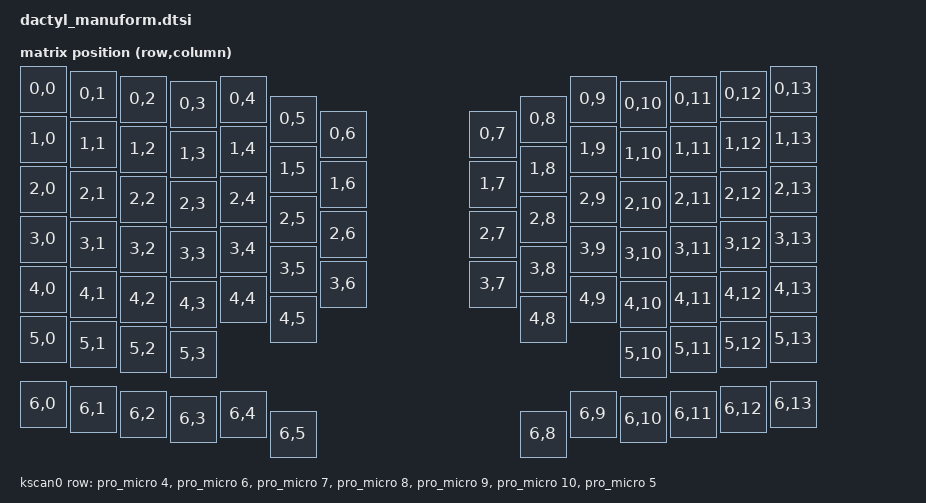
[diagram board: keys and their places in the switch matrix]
#include <dt-bindings/zmk/matrix_transform.h>
#include <physical_layouts.dtsi>

/ {
	chosen {
		zmk,kscan = &kscan0;
		zmk,physical-layout = &dactyl_manuform_layout;
	};

	dactyl_manuform_layout: dactyl_manuform_layout {
		compatible = "zmk,physical-layout";
		display-name = "7x7";
		transform = <&default_transform>;

		keys = <&key_physical_attrs 100 100 0 0 0 0 0>
			, <&key_physical_attrs 100 100 100 10 0 0 0>
			, <&key_physical_attrs 100 100 200 20 0 0 0>
			, <&key_physical_attrs 100 100 300 30 0 0 0>
			, <&key_physical_attrs 100 100 400 20 0 0 0>
			, <&key_physical_attrs 100 100 500 60 0 0 0>
			, <&key_physical_attrs 100 100 600 90 0 0 0>
			, <&key_physical_attrs 100 100 900 90 0 0 0>
			, <&key_physical_attrs 100 100 1000 60 0 0 0>
			, <&key_physical_attrs 100 100 1100 20 0 0 0>
			, <&key_physical_attrs 100 100 1200 30 0 0 0>
			, <&key_physical_attrs 100 100 1300 20 0 0 0>
			, <&key_physical_attrs 100 100 1400 10 0 0 0>
			, <&key_physical_attrs 100 100 1500 0 0 0 0>
			, <&key_physical_attrs 100 100 0 100 0 0 0>
			, <&key_physical_attrs 100 100 100 110 0 0 0>
			, <&key_physical_attrs 100 100 200 120 0 0 0>
			, <&key_physical_attrs 100 100 300 130 0 0 0>
			, <&key_physical_attrs 100 100 400 120 0 0 0>
			, <&key_physical_attrs 100 100 500 160 0 0 0>
			, <&key_physical_attrs 100 100 600 190 0 0 0>
			, <&key_physical_attrs 100 100 900 190 0 0 0>
			, <&key_physical_attrs 100 100 1000 160 0 0 0>
			, <&key_physical_attrs 100 100 1100 120 0 0 0>
			, <&key_physical_attrs 100 100 1200 130 0 0 0>
			, <&key_physical_attrs 100 100 1300 120 0 0 0>
			, <&key_physical_attrs 100 100 1400 110 0 0 0>
			, <&key_physical_attrs 100 100 1500 100 0 0 0>
			, <&key_physical_attrs 100 100 0 200 0 0 0>
			, <&key_physical_attrs 100 100 100 210 0 0 0>
			, <&key_physical_attrs 100 100 200 220 0 0 0>
			, <&key_physical_attrs 100 100 300 230 0 0 0>
			, <&key_physical_attrs 100 100 400 220 0 0 0>
			, <&key_physical_attrs 100 100 500 260 0 0 0>
			, <&key_physical_attrs 100 100 600 290 0 0 0>
			, <&key_physical_attrs 100 100 900 290 0 0 0>
			, <&key_physical_attrs 100 100 1000 260 0 0 0>
			, <&key_physical_attrs 100 100 1100 220 0 0 0>
			, <&key_physical_attrs 100 100 1200 230 0 0 0>
			, <&key_physical_attrs 100 100 1300 220 0 0 0>
			, <&key_physical_attrs 100 100 1400 210 0 0 0>
			, <&key_physical_attrs 100 100 1500 200 0 0 0>
			, <&key_physical_attrs 100 100 0 300 0 0 0>
			, <&key_physical_attrs 100 100 100 310 0 0 0>
			, <&key_physical_attrs 100 100 200 320 0 0 0>
			, <&key_physical_attrs 100 100 300 330 0 0 0>
			, <&key_physical_attrs 100 100 400 320 0 0 0>
			, <&key_physical_attrs 100 100 500 360 0 0 0>
			, <&key_physical_attrs 100 100 600 390 0 0 0>
			, <&key_physical_attrs 100 100 900 390 0 0 0>
			, <&key_physical_attrs 100 100 1000 360 0 0 0>
			, <&key_physical_attrs 100 100 1100 320 0 0 0>
			, <&key_physical_attrs 100 100 1200 330 0 0 0>
			, <&key_physical_attrs 100 100 1300 320 0 0 0>
			, <&key_physical_attrs 100 100 1400 310 0 0 0>
			, <&key_physical_attrs 100 100 1500 300 0 0 0>
			, <&key_physical_attrs 100 100 0 400 0 0 0>
			, <&key_physical_attrs 100 100 100 410 0 0 0>
			, <&key_physical_attrs 100 100 200 420 0 0 0>
			, <&key_physical_attrs 100 100 300 430 0 0 0>
			, <&key_physical_attrs 100 100 400 420 0 0 0>
			, <&key_physical_attrs 100 100 500 460 0 0 0>
			, <&key_physical_attrs 100 100 1000 460 0 0 0>
			, <&key_physical_attrs 100 100 1100 420 0 0 0>
			, <&key_physical_attrs 100 100 1200 430 0 0 0>
			, <&key_physical_attrs 100 100 1300 420 0 0 0>
			, <&key_physical_attrs 100 100 1400 410 0 0 0>
			, <&key_physical_attrs 100 100 1500 400 0 0 0>
			, <&key_physical_attrs 100 100 0 500 0 0 0>
			, <&key_physical_attrs 100 100 100 510 0 0 0>
			, <&key_physical_attrs 100 100 200 520 0 0 0>
			, <&key_physical_attrs 100 100 300 530 0 0 0>
			, <&key_physical_attrs 100 100 1200 530 0 0 0>
			, <&key_physical_attrs 100 100 1300 520 0 0 0>
			, <&key_physical_attrs 100 100 1400 510 0 0 0>
			, <&key_physical_attrs 100 100 1500 500 0 0 0>
			, <&key_physical_attrs 100 100 0 630 0 0 0>
			, <&key_physical_attrs 100 100 100 640 0 0 0>
			, <&key_physical_attrs 100 100 200 650 0 0 0>
			, <&key_physical_attrs 100 100 300 660 0 0 0>
			, <&key_physical_attrs 100 100 400 650 0 0 0>
			, <&key_physical_attrs 100 100 500 690 0 0 0>
			, <&key_physical_attrs 100 100 1000 690 0 0 0>
			, <&key_physical_attrs 100 100 1100 650 0 0 0>
			, <&key_physical_attrs 100 100 1200 660 0 0 0>
			, <&key_physical_attrs 100 100 1300 650 0 0 0>
			, <&key_physical_attrs 100 100 1400 640 0 0 0>
			, <&key_physical_attrs 100 100 1500 630 0 0 0>
		;
	};

	default_transform: keymap_transform_0 {
		compatible = "zmk,matrix-transform";
		columns = <14>;
		rows = <7>;
		map = <
RC(0,0) RC(0,1) RC(0,2) RC(0,3) RC(0,4) RC(0,5) RC(0,6)                                   RC(0,7) RC(0,8) RC(0,9) RC(0,10) RC(0,11) RC(0,12) RC(0,13)
RC(1,0) RC(1,1) RC(1,2) RC(1,3) RC(1,4) RC(1,5) RC(1,6)                                   RC(1,7) RC(1,8) RC(1,9) RC(1,10) RC(1,11) RC(1,12) RC(1,13)
RC(2,0) RC(2,1) RC(2,2) RC(2,3) RC(2,4) RC(2,5) RC(2,6)                                   RC(2,7) RC(2,8) RC(2,9) RC(2,10) RC(2,11) RC(2,12) RC(2,13)
RC(3,0) RC(3,1) RC(3,2) RC(3,3) RC(3,4) RC(3,5) RC(3,6)                                   RC(3,7) RC(3,8) RC(3,9) RC(3,10) RC(3,11) RC(3,12) RC(3,13)
RC(4,0) RC(4,1) RC(4,2) RC(4,3) RC(4,4) RC(4,5)                                                      RC(4,8) RC(4,9) RC(4,10) RC(4,11) RC(4,12) RC(4,13)
RC(5,0) RC(5,1) RC(5,2) RC(5,3)                                                                                      RC(5,10) RC(5,11) RC(5,12) RC(5,13)
RC(6,0) RC(6,1) RC(6,2) RC(6,3) RC(6,4) RC(6,5)                                                   RC(6,8) RC(6,9) RC(6,10) RC(6,11) RC(6,12) RC(6,13)
		>;
	};

	kscan0: kscan {
		compatible = "zmk,kscan-gpio-matrix";
		wakeup-source;

		diode-direction = "col2row";
		row-gpios
			= <&pro_micro 4 (GPIO_ACTIVE_HIGH | GPIO_PULL_DOWN)>
			, <&pro_micro 6 (GPIO_ACTIVE_HIGH | GPIO_PULL_DOWN)>
			, <&pro_micro 7 (GPIO_ACTIVE_HIGH | GPIO_PULL_DOWN)>
			, <&pro_micro 8 (GPIO_ACTIVE_HIGH | GPIO_PULL_DOWN)>
			, <&pro_micro 9 (GPIO_ACTIVE_HIGH | GPIO_PULL_DOWN)>
			, <&pro_micro 10 (GPIO_ACTIVE_HIGH | GPIO_PULL_DOWN)>
			, <&pro_micro 5 (GPIO_ACTIVE_HIGH | GPIO_PULL_DOWN)>
			;
	};
};
